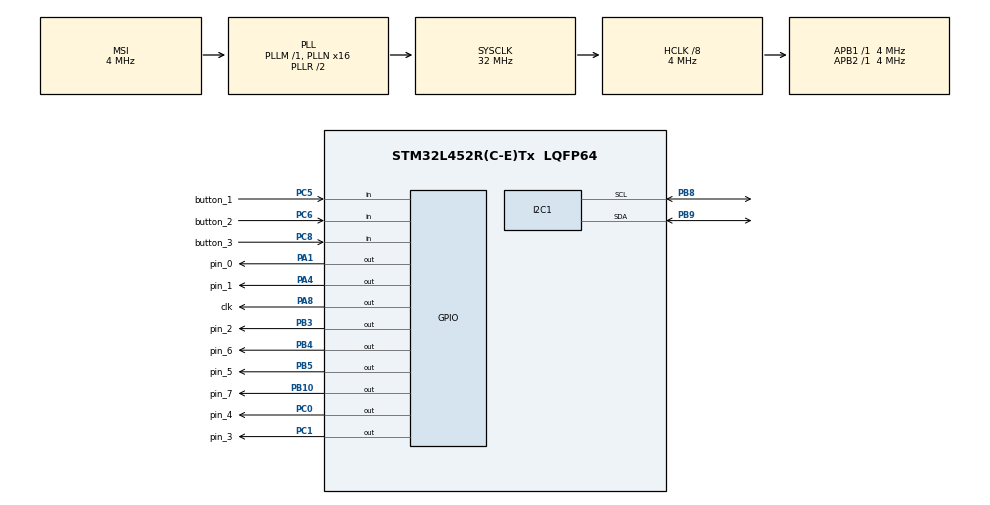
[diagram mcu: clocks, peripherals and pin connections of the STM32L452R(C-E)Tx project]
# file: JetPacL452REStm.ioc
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FREERTOS.Tasks01=defaultTask,0,128,StartDefaultTask,Default,NULL
Mcu.Family=STM32L4
Mcu.Name=STM32L452R(C-E)Tx
Mcu.Package=LQFP64
NVIC.PriorityGroup=NVIC_PRIORITYGROUP_4
NVIC.TIM1_UP_TIM16_IRQn=true\:0\:0\:false\:false\:true\:false\:false
NVIC.TimeBase=TIM1_UP_TIM16_IRQn
NVIC.TimeBaseIP=TIM1
PA1.GPIO_Label=pin_0
PA1.Signal=GPIO_Output
PA4.GPIO_Label=pin_1
PA4.Signal=GPIO_Output
PA8.GPIO_Label=clk
PA8.Signal=GPIO_Output
PB10.GPIO_Label=pin_7
PB10.Signal=GPIO_Output
PB3\ (JTDO/TRACESWO).GPIO_Label=pin_2
PB3\ (JTDO/TRACESWO).Signal=GPIO_Output
PB4\ (NJTRST).GPIO_Label=pin_6
PB4\ (NJTRST).Signal=GPIO_Output
PB5.GPIO_Label=pin_5
PB5.Signal=GPIO_Output
PB8.Mode=I2C
PB8.Signal=I2C1_SCL
PB9.Mode=I2C
PB9.Signal=I2C1_SDA
PC0.GPIO_Label=pin_4
PC0.Signal=GPIO_Output
PC1.GPIO_Label=pin_3
PC1.Signal=GPIO_Output
PC5.GPIO_Label=button_1
PC5.GPIO_Mode=GPIO_MODE_INPUT
PC5.GPIO_PuPd=GPIO_PULLUP
PC5.Signal=GPIO_Input
PC6.GPIO_Label=button_2
PC6.GPIO_Mode=GPIO_MODE_INPUT
PC6.GPIO_PuPd=GPIO_PULLUP
PC6.Signal=GPIO_Input
PC8.GPIO_Label=button_3
PC8.GPIO_Mode=GPIO_MODE_INPUT
PC8.GPIO_PuPd=GPIO_PULLUP
PC8.Signal=GPIO_Input
ProjectManager.HeapSize=0x200
ProjectManager.StackSize=0x400
ProjectManager.TargetToolchain=SW4STM32
RCC.AHBCLKDivider=RCC_SYSCLK_DIV8
RCC.AHBFreq_Value=4000000
RCC.APB1Freq_Value=4000000
RCC.APB1TimFreq_Value=4000000
RCC.APB2Freq_Value=4000000
RCC.APB2TimFreq_Value=4000000
RCC.CortexFreq_Value=4000000
RCC.HCLKFreq_Value=4000000
RCC.HSE_VALUE=8000000
RCC.HSI48_VALUE=48000000
RCC.HSI_VALUE=16000000
RCC.LSE_VALUE=32768
RCC.MSI_VALUE=4000000
RCC.PLLN=16
RCC.SYSCLKFreq_VALUE=32000000
RCC.SYSCLKSource=RCC_SYSCLKSOURCE_PLLCLK
RCC.VCOOutputFreq_Value=64000000
VP_FREERTOS_VS_ENABLE.Mode=Enabled
VP_SYS_VS_tim1.Mode=TIM1
board=custom

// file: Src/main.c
/**
  ******************************************************************************
  * @file           : main.c
  * @brief          : Main program body
  ******************************************************************************
  * This notice applies to any and all portions of this file
  * that are not between comment pairs USER CODE BEGIN and
  * USER CODE END. Other portions of this file, whether
  * inserted by the user or by software development tools
  * are owned by their respective copyright owners.
  *
  * Copyright (c) 2019 STMicroelectronics International N.V.
  * All rights reserved.
  *
  * Redistribution and use in source and binary forms, with or without
  * modification, are permitted, provided that the following conditions are met:
  *
  * 1. Redistribution of source code must retain the above copyright notice,
  *    this list of conditions and the following disclaimer.
  * 2. Redistributions in binary form must reproduce the above copyright notice,
  *    this list of conditions and the following disclaimer in the documentation
  *    and/or other materials provided with the distribution.
  * 3. Neither the name of STMicroelectronics nor the names of other
  *    contributors to this software may be used to endorse or promote products
  *    derived from this software without specific written permission.
  * 4. This software, including modifications and/or derivative works of this
  *    software, must execute solely and exclusively on microcontroller or
  *    microprocessor devices manufactured by or for STMicroelectronics.
  * 5. Redistribution and use of this software other than as permitted under
  *    this license is void and will automatically terminate your rights under
  *    this license.
  *
  * THIS SOFTWARE IS PROVIDED BY STMICROELECTRONICS AND CONTRIBUTORS "AS IS"
  * AND ANY EXPRESS, IMPLIED OR STATUTORY WARRANTIES, INCLUDING, BUT NOT
  * LIMITED TO, THE IMPLIED WARRANTIES OF MERCHANTABILITY, FITNESS FOR A
  * PARTICULAR PURPOSE AND NON-INFRINGEMENT OF THIRD PARTY INTELLECTUAL PROPERTY
  * RIGHTS ARE DISCLAIMED TO THE FULLEST EXTENT PERMITTED BY LAW. IN NO EVENT
  * SHALL STMICROELECTRONICS OR CONTRIBUTORS BE LIABLE FOR ANY DIRECT, INDIRECT,
  * INCIDENTAL, SPECIAL, EXEMPLARY, OR CONSEQUENTIAL DAMAGES (INCLUDING, BUT NOT
  * LIMITED TO, PROCUREMENT OF SUBSTITUTE GOODS OR SERVICES; LOSS OF USE, DATA,
  * OR PROFITS; OR BUSINESS INTERRUPTION) HOWEVER CAUSED AND ON ANY THEORY OF
  * LIABILITY, WHETHER IN CONTRACT, STRICT LIABILITY, OR TORT (INCLUDING
  * NEGLIGENCE OR OTHERWISE) ARISING IN ANY WAY OUT OF THE USE OF THIS SOFTWARE,
  * EVEN IF ADVISED OF THE POSSIBILITY OF SUCH DAMAGE.
  *
  ******************************************************************************
  */
#include "main.h"
#include "stm32l4xx_hal.h"
#include "cmsis_os.h"

/* USER CODE BEGIN Includes */
#include "tasks.h"
/* USER CODE END Includes */

I2C_HandleTypeDef hi2c1;

osThreadId defaultTaskHandle;

/* USER CODE BEGIN PV */
/* Private variables ---------------------------------------------------------*/

/* USER CODE END PV */

void SystemClock_Config(void);
static void MX_GPIO_Init(void);
static void MX_I2C1_Init(void);
void StartDefaultTask(void const * argument);

/* USER CODE BEGIN PFP */
/* Private function prototypes -----------------------------------------------*/

/* USER CODE END PFP */

int main(void)
{

  /* MCU Configuration----------------------------------------------------------*/

  /* Reset of all peripherals, Initializes the Flash interface and the Systick. */
  HAL_Init();

  /* Configure the system clock */
  SystemClock_Config();

  /* Initialize all configured peripherals */
  MX_GPIO_Init();
  MX_I2C1_Init();

  /* Create the thread(s) */
  /* definition and creation of defaultTask */
  osThreadDef(defaultTask, StartDefaultTask, osPriorityNormal, 0, 128);
  defaultTaskHandle = osThreadCreate(osThread(defaultTask), NULL);

  /* USER CODE BEGIN RTOS_THREADS */
  /* add threads, ... */
  xTaskCreate(cppmaintask_1,(char *)"CppMain",configMINIMAL_STACK_SIZE,NULL,3,NULL);
  //xTaskCreate(cppmaintask_2,(char *)"CppMain",configMINIMAL_STACK_SIZE,NULL,3,NULL);
  /* USER CODE END RTOS_THREADS */

  /* Start scheduler */
  osKernelStart();

  /* We should never get here as control is now taken by the scheduler */

  /* Infinite loop */
  while (1)
  {

  }

}

void SystemClock_Config(void)
{

  RCC_OscInitTypeDef RCC_OscInitStruct;
  RCC_ClkInitTypeDef RCC_ClkInitStruct;
  RCC_PeriphCLKInitTypeDef PeriphClkInit;

    /**Initializes the CPU, AHB and APB busses clocks
    */
  RCC_OscInitStruct.OscillatorType = RCC_OSCILLATORTYPE_MSI;
  RCC_OscInitStruct.MSIState = RCC_MSI_ON;
  RCC_OscInitStruct.MSICalibrationValue = 0;
  RCC_OscInitStruct.MSIClockRange = RCC_MSIRANGE_6;
  RCC_OscInitStruct.PLL.PLLState = RCC_PLL_ON;
  RCC_OscInitStruct.PLL.PLLSource = RCC_PLLSOURCE_MSI;
  RCC_OscInitStruct.PLL.PLLM = 1;
  RCC_OscInitStruct.PLL.PLLN = 16;
  RCC_OscInitStruct.PLL.PLLP = RCC_PLLP_DIV7;
  RCC_OscInitStruct.PLL.PLLQ = RCC_PLLQ_DIV2;
  RCC_OscInitStruct.PLL.PLLR = RCC_PLLR_DIV2;
  if (HAL_RCC_OscConfig(&RCC_OscInitStruct) != HAL_OK)
  {
    _Error_Handler(__FILE__, __LINE__);
  }

    /**Initializes the CPU, AHB and APB busses clocks
    */
  RCC_ClkInitStruct.ClockType = RCC_CLOCKTYPE_HCLK|RCC_CLOCKTYPE_SYSCLK
                              |RCC_CLOCKTYPE_PCLK1|RCC_CLOCKTYPE_PCLK2;
  RCC_ClkInitStruct.SYSCLKSource = RCC_SYSCLKSOURCE_PLLCLK;
  RCC_ClkInitStruct.AHBCLKDivider = RCC_SYSCLK_DIV8;
  RCC_ClkInitStruct.APB1CLKDivider = RCC_HCLK_DIV1;
  RCC_ClkInitStruct.APB2CLKDivider = RCC_HCLK_DIV1;

  if (HAL_RCC_ClockConfig(&RCC_ClkInitStruct, FLASH_LATENCY_0) != HAL_OK)
  {
    _Error_Handler(__FILE__, __LINE__);
  }

  PeriphClkInit.PeriphClockSelection = RCC_PERIPHCLK_I2C1;
  PeriphClkInit.I2c1ClockSelection = RCC_I2C1CLKSOURCE_PCLK1;
  if (HAL_RCCEx_PeriphCLKConfig(&PeriphClkInit) != HAL_OK)
  {
    _Error_Handler(__FILE__, __LINE__);
  }

    /**Configure the main internal regulator output voltage
    */
  if (HAL_PWREx_ControlVoltageScaling(PWR_REGULATOR_VOLTAGE_SCALE1) != HAL_OK)
  {
    _Error_Handler(__FILE__, __LINE__);
  }

    /**Configure the Systick interrupt time
    */
  HAL_SYSTICK_Config(HAL_RCC_GetHCLKFreq()/1000);

    /**Configure the Systick
    */
  HAL_SYSTICK_CLKSourceConfig(SYSTICK_CLKSOURCE_HCLK);

  /* SysTick_IRQn interrupt configuration */
  HAL_NVIC_SetPriority(SysTick_IRQn, 15, 0);
}

/* I2C1 init function */
static void MX_I2C1_Init(void)
{

  hi2c1.Instance = I2C1;
  hi2c1.Init.Timing = 0x00000E14;
  hi2c1.Init.OwnAddress1 = 0;
  hi2c1.Init.AddressingMode = I2C_ADDRESSINGMODE_7BIT;
  hi2c1.Init.DualAddressMode = I2C_DUALADDRESS_DISABLE;
  hi2c1.Init.OwnAddress2 = 0;
  hi2c1.Init.OwnAddress2Masks = I2C_OA2_NOMASK;
  hi2c1.Init.GeneralCallMode = I2C_GENERALCALL_DISABLE;
  hi2c1.Init.NoStretchMode = I2C_NOSTRETCH_DISABLE;
  if (HAL_I2C_Init(&hi2c1) != HAL_OK)
  {
    _Error_Handler(__FILE__, __LINE__);
  }

    /**Configure Analogue filter
    */
  if (HAL_I2CEx_ConfigAnalogFilter(&hi2c1, I2C_ANALOGFILTER_ENABLE) != HAL_OK)
  {
    _Error_Handler(__FILE__, __LINE__);
  }

    /**Configure Digital filter
    */
  if (HAL_I2CEx_ConfigDigitalFilter(&hi2c1, 0) != HAL_OK)
  {
    _Error_Handler(__FILE__, __LINE__);
  }

}

/** Configure pins as
        * Analog
        * Input
        * Output
        * EVENT_OUT
        * EXTI
*/
static void MX_GPIO_Init(void)
{

  GPIO_InitTypeDef GPIO_InitStruct;

  /* GPIO Ports Clock Enable */
  __HAL_RCC_GPIOC_CLK_ENABLE();
  __HAL_RCC_GPIOA_CLK_ENABLE();
  __HAL_RCC_GPIOB_CLK_ENABLE();

  /*Configure GPIO pin Output Level */
  HAL_GPIO_WritePin(GPIOC, pin_4_Pin|pin_3_Pin, GPIO_PIN_RESET);

  /*Configure GPIO pin Output Level */
  HAL_GPIO_WritePin(GPIOA, pin_0_Pin|pin_1_Pin|clk_Pin, GPIO_PIN_RESET);

  /*Configure GPIO pin Output Level */
  HAL_GPIO_WritePin(GPIOB, pin_7_Pin|pin_2_Pin|pin_6_Pin|pin_5_Pin, GPIO_PIN_RESET);

  /*Configure GPIO pins : pin_4_Pin pin_3_Pin */
  GPIO_InitStruct.Pin = pin_4_Pin|pin_3_Pin;
  GPIO_InitStruct.Mode = GPIO_MODE_OUTPUT_PP;
  GPIO_InitStruct.Pull = GPIO_NOPULL;
  GPIO_InitStruct.Speed = GPIO_SPEED_FREQ_LOW;
  HAL_GPIO_Init(GPIOC, &GPIO_InitStruct);

  /*Configure GPIO pins : pin_0_Pin pin_1_Pin clk_Pin */
  GPIO_InitStruct.Pin = pin_0_Pin|pin_1_Pin|clk_Pin;
  GPIO_InitStruct.Mode = GPIO_MODE_OUTPUT_PP;
  GPIO_InitStruct.Pull = GPIO_NOPULL;
  GPIO_InitStruct.Speed = GPIO_SPEED_FREQ_LOW;
  HAL_GPIO_Init(GPIOA, &GPIO_InitStruct);

  /*Configure GPIO pins : button_1_Pin button_2_Pin button_3_Pin */
  GPIO_InitStruct.Pin = button_1_Pin|button_2_Pin|button_3_Pin;
  GPIO_InitStruct.Mode = GPIO_MODE_INPUT;
  GPIO_InitStruct.Pull = GPIO_PULLUP;
  HAL_GPIO_Init(GPIOC, &GPIO_InitStruct);

  /*Configure GPIO pins : pin_7_Pin pin_2_Pin pin_6_Pin pin_5_Pin */
  GPIO_InitStruct.Pin = pin_7_Pin|pin_2_Pin|pin_6_Pin|pin_5_Pin;
  GPIO_InitStruct.Mode = GPIO_MODE_OUTPUT_PP;
  GPIO_InitStruct.Pull = GPIO_NOPULL;
  GPIO_InitStruct.Speed = GPIO_SPEED_FREQ_LOW;
  HAL_GPIO_Init(GPIOB, &GPIO_InitStruct);

}

/* StartDefaultTask function */
void StartDefaultTask(void const * argument)
{

  for(;;)
  {
    osDelay(1);
  }
}

void HAL_TIM_PeriodElapsedCallback(TIM_HandleTypeDef *htim)
{
  if (htim->Instance == TIM1) {
    HAL_IncTick();
  }
}

void _Error_Handler(char *file, int line)
{
  while(1)
  {
  }
}

/************************ (C) COPYRIGHT STMicroelectronics *****END OF FILE****/
